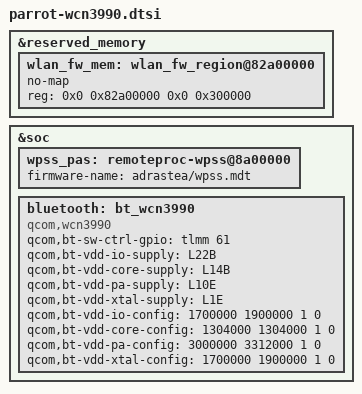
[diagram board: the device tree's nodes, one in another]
// SPDX-License-Identifier: BSD-3-Clause
/*
 * Copyright (c) 2024 Qualcomm Innovation Center, Inc. All rights reserved.
 */

#include <dt-bindings/interrupt-controller/arm-gic.h>
#include <dt-bindings/gpio/gpio.h>

&reserved_memory {
	wlan_fw_mem: wlan_fw_region@82a00000 {
		no-map;
		reg = <0x0 0x82a00000 0x0 0x300000>;
	};
};

&soc {
	wpss_pas: remoteproc-wpss@8a00000 {
		firmware-name = "adrastea/wpss.mdt";
	};

	bluetooth: bt_wcn3990 {
		compatible = "qcom,wcn3990";
		qcom,bt-sw-ctrl-gpio = <&tlmm 61 GPIO_ACTIVE_HIGH>;
		qcom,bt-vdd-io-supply = <&L22B>;  /* IO */
		qcom,bt-vdd-core-supply = <&L14B>; /* RFA */
		qcom,bt-vdd-pa-supply = <&L10E>; /* CH0 */
		qcom,bt-vdd-xtal-supply = <&L1E>; /* XO */

		qcom,bt-vdd-io-config = <1700000 1900000 1 0>;
		qcom,bt-vdd-core-config = <1304000 1304000 1 0>;
		qcom,bt-vdd-pa-config = <3000000 3312000 1 0>;
		qcom,bt-vdd-xtal-config = <1700000 1900000 1 0>;
	};
};
